# L4PER_PRM register map
Vendor: Texas Instruments
Peripheral module from a debugger description file (folder am572x).
Registers are 32-bit, access per field, reset 0x0 unless marked. A register's access mark holds for its fields unless they carry their own. Offsets are as the file gives them; lines under a group give offsets from that group; [hi:lo] are bit positions; {n}, {i} and the like mark numbered series; 'fields as' and 'values as' point back to an identical list; <NAME> marks a mode.

## L4PER_PRM (part 1 of 2)
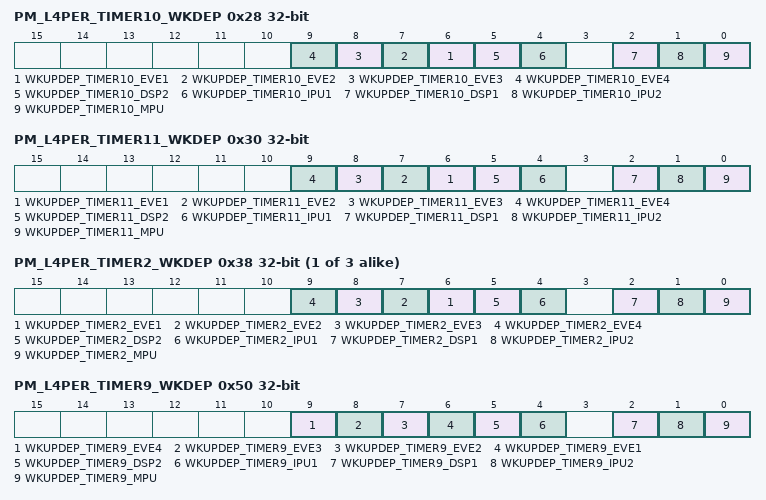
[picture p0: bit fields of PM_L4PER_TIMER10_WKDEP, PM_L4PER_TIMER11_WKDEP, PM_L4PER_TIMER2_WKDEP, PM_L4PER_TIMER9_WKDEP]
0x28 PM_L4PER_TIMER10_WKDEP — This register controls wakeup dependency based on TIMER10 service requests.
  [all] fields
    0=DISABLED (Dependency is disabled); 1=ENABLED (Dependency is enabled)
  [n+5] WKUPDEP_TIMER10_EVE{n} rw (n=1..4) — Wakeup dependency from TIMER10 module (SWakeup IRQ signal) towards EVE{n} + L3_MAIN1 + L4PER1 + L4PER2 + L4PER3 domains
  [5] WKUPDEP_TIMER10_DSP2 rw — Wakeup dependency from TIMER10 module (SWakeup IRQ signal) towards DSP2 + L3_MAIN1 + L4PER1 + L4PER2 + L4PER3 domains
  [4] WKUPDEP_TIMER10_IPU1 rw — Wakeup dependency from TIMER10 module (SWakeup IRQ signal) towards IPU1 + L3_MAIN1 + L4PER1 + L4PER2 + L4PER3 domains
  [2] WKUPDEP_TIMER10_DSP1 rw — Wakeup dependency from TIMER10 module (SWakeup IRQ signal) towards DSP + L3MAIN1 + L4PER1 + L4PER2 + L4PER3 domains
  [1] WKUPDEP_TIMER10_IPU2 rw — Wakeup dependency from TIMER10 module (SWakeup IRQ signal) towards IPU2 + L3_MAIN1 + L4PER1 + L4PER2 + L4PER3 domains
  [0] WKUPDEP_TIMER10_MPU rw — Wakeup dependency from TIMER10 module (SWakeup IRQ signal) towards MPU + L3_MAIN1 + L4PER1 + L4PER2 + L4PER3 domains
0x30 PM_L4PER_TIMER11_WKDEP — This register controls wakeup dependency based on TIMER11 service requests.
  [all] fields
    values as the fields of PM_L4PER_TIMER10_WKDEP
  [n+5] WKUPDEP_TIMER11_EVE{n} rw (n=1..4) — Wakeup dependency from TIMER11 module (SWakeup IRQ signal) towards EVE{n} + L3_MAIN1 + L4PER1 + L4PER2 + L4PER3 domains
  [5] WKUPDEP_TIMER11_DSP2 rw — Wakeup dependency from TIMER11 module (SWakeup IRQ signal) towards DSP2 + L3_MAIN1 + L4PER1 + L4PER2 + L4PER3 domains
  [4] WKUPDEP_TIMER11_IPU1 rw — Wakeup dependency from TIMER11 module (SWakeup IRQ signal) towards IPU1 + L3_MAIN1 + L4PER1 + L4PER2 + L4PER3 domains
  [2] WKUPDEP_TIMER11_DSP1 rw — Wakeup dependency from TIMER11 module (SWakeup IRQ signal) towards DSP + L3MAIN1 + L4PER1 + L4PER2 + L4PER3 domains
  [1] WKUPDEP_TIMER11_IPU2 rw — Wakeup dependency from TIMER11 module (SWakeup IRQ signal) towards IPU2 + L3_MAIN1 + L4PER1 + L4PER2 + L4PER3 domains
  [0] WKUPDEP_TIMER11_MPU rw — Wakeup dependency from TIMER11 module (SWakeup IRQ signal) towards MPU + L3_MAIN1 + L4PER1 + L4PER2 + L4PER3 domains
{0x28+8i} PM_L4PER_TIMER{i}_WKDEP (i=2..4) — This register controls wakeup dependency based on TIMER{i} service requests.
  [all] fields
    values as the fields of PM_L4PER_TIMER10_WKDEP
  [n+5] WKUPDEP_TIMER{i}_EVE{n} rw (n=1..4) — Wakeup dependency from TIMER{i} module (SWakeup IRQ signal) towards EVE{n} + L3_MAIN1 + L4PER1 + L4PER2 + L4PER3 domains
  [5] WKUPDEP_TIMER{i}_DSP2 rw — Wakeup dependency from TIMER{i} module (SWakeup IRQ signal) towards DSP2 + L3_MAIN1 + L4PER1 + L4PER2 + L4PER3 domains
  [4] WKUPDEP_TIMER{i}_IPU1 rw — Wakeup dependency from TIMER{i} module (SWakeup IRQ signal) towards IPU1 + L3_MAIN1 + L4PER1 + L4PER2 + L4PER3 domains
  [2] WKUPDEP_TIMER{i}_DSP1 rw — Wakeup dependency from TIMER{i} module (SWakeup IRQ signal) towards DSP + L3MAIN1 + L4PER1 + L4PER2 + L4PER3 domains
  [1] WKUPDEP_TIMER{i}_IPU2 rw — Wakeup dependency from TIMER{i} module (SWakeup IRQ signal) towards IPU2 + L3_MAIN1 + L4PER1 + L4PER2 + L4PER3 domains
  [0] WKUPDEP_TIMER{i}_MPU rw — Wakeup dependency from TIMER{i} module (SWakeup IRQ signal) towards MPU + L3_MAIN1 + L4PER1 + L4PER2 + L4PER3 domains
0x50 PM_L4PER_TIMER9_WKDEP — This register controls wakeup dependency based on TIMER9 service requests.
  [all] fields
    values as the fields of PM_L4PER_TIMER10_WKDEP
  [9] WKUPDEP_TIMER9_EVE4 rw — Wakeup dependency from TIMER9 module (SWakeup IRQ signal) towards EVE4 + L3_MAIN1 + L4PER1 + L4PER2 + L4PER3 domains
  [8] WKUPDEP_TIMER9_EVE3 rw — Wakeup dependency from TIMER9 module (SWakeup IRQ signal) towards EVE3 + L3_MAIN1 + L4PER1 + L4PER2 + L4PER3 domains
  [7] WKUPDEP_TIMER9_EVE2 rw — ×(SWakeup IRQ signal) towards EVE2 + L3_MAIN1 + L4PER1 + L4PER2 + L4PER3 domains
  [6] WKUPDEP_TIMER9_EVE1 rw — Wakeup dependency from TIMER9 module (SWakeup IRQ signal) towards EVE1 + L3_MAIN1 + L4PER1 + L4PER2 + L4PER3 domains
  [5] WKUPDEP_TIMER9_DSP2 rw — Wakeup dependency from TIMER9 module (SWakeup IRQ signal) towards DSP2 + L3_MAIN1 + L4PER1 + L4PER2 + L4PER3 domains
  [4] WKUPDEP_TIMER9_IPU1 rw — Wakeup dependency from TIMER9 module (SWakeup IRQ signal) towards IPU1 + L3_MAIN1 + L4PER1 + L4PER2 + L4PER3 domains
  [2] WKUPDEP_TIMER9_DSP1 rw — Wakeup dependency from TIMER9 module (SWakeup IRQ signal) towards DSP + L3MAIN1 + L4PER1 + L4PER2 + L4PER3 domains
  [1] WKUPDEP_TIMER9_IPU2 rw — Wakeup dependency from TIMER9 module (SWakeup IRQ signal) towards IPU2 + L3_MAIN1 + L4PER1 + L4PER2 + L4PER3 domains
  [0] WKUPDEP_TIMER9_MPU rw — Wakeup dependency from TIMER9 module (SWakeup IRQ signal) towards MPU + L3_MAIN1 + L4PER1 + L4PER2 + L4PER3 domains
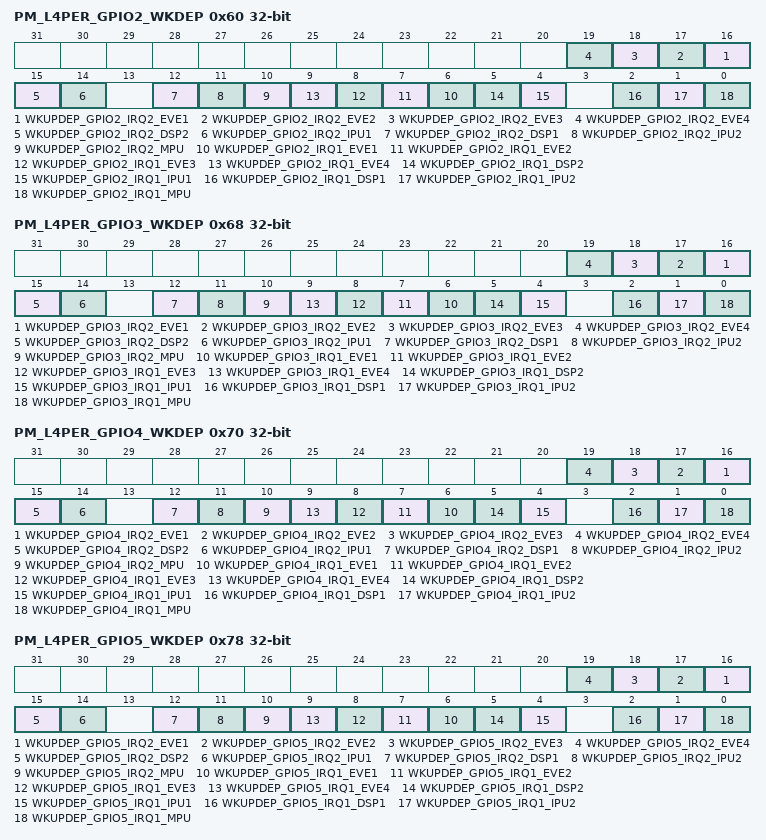
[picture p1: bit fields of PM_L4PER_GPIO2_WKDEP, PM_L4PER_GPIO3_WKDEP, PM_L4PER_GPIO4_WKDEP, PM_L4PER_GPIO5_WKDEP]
0x60 PM_L4PER_GPIO2_WKDEP — This register controls wakeup dependency based on GPIO2 service requests.
  [all] fields
    values as the fields of PM_L4PER_TIMER10_WKDEP
  [n+15] WKUPDEP_GPIO2_IRQ2_EVE{n} rw (n=1..4) — Wakeup dependency from GPIO2 module (SWakeup signal) towards EVE{n} + L3_MAIN1 + L4PER1 + L4PER2 + L4PER3 domains
  [15] WKUPDEP_GPIO2_IRQ2_DSP2 rw — Wakeup dependency from GPIO2 module (SWakeup signal) towards DSP2 + L3_MAIN1 + L4PER1 + L4PER2 + L4PER3 domains
  [14] WKUPDEP_GPIO2_IRQ2_IPU1 rw — Wakeup dependency from GPIO2 module (SWakeup signal) towards IPU1 + L3_MAIN1 + L4PER1 + L4PER2 + L4PER3 domains
  [12] WKUPDEP_GPIO2_IRQ2_DSP1 rw — Wakeup dependency from GPIO2 module (SWakeup signal) towards DSP + L3MAIN1 + L4PER1 + L4PER2 + L4PER3 domains
  [11] WKUPDEP_GPIO2_IRQ2_IPU2 rw — Wakeup dependency from GPIO2 module (SWakeup signal) towards IPU2 + L3_MAIN1 + L4PER1 + L4PER2 + L4PER3 domains
  [10] WKUPDEP_GPIO2_IRQ2_MPU rw — Wakeup dependency from GPIO2 module (SWakeup signal) towards MPU + L3_MAIN1 + L4PER1 + L4PER2 + L4PER3 domains
  [n+5] WKUPDEP_GPIO2_IRQ1_EVE{n} rw (n=1..4) — Wakeup dependency from GPIO2 module (SWakeup signal) towards EVE{n} + L3_MAIN1 + L4PER1 + L4PER2 + L4PER3 domains
  [5] WKUPDEP_GPIO2_IRQ1_DSP2 rw — Wakeup dependency from GPIO2 module (SWakeup signal) towards DSP2 + L3_MAIN1 + L4PER1 + L4PER2 + L4PER3 domains
  [4] WKUPDEP_GPIO2_IRQ1_IPU1 rw — Wakeup dependency from GPIO2 module (SWakeup signal) towards IPU1 + L3_MAIN1 + L4PER1 + L4PER2 + L4PER3 domains
  [2] WKUPDEP_GPIO2_IRQ1_DSP1 rw — Wakeup dependency from GPIO2 module (SWakeup signal) towards DSP + L3MAIN1 + L4PER1 + L4PER2 + L4PER3 domains
  [1] WKUPDEP_GPIO2_IRQ1_IPU2 rw — Wakeup dependency from GPIO2 module (SWakeup signal) towards IPU2 + L3_MAIN1 + L4PER1 + L4PER2 + L4PER3 domains
  [0] WKUPDEP_GPIO2_IRQ1_MPU rw — Wakeup dependency from GPIO2 module (SWakeup signal for POROCPSINTERRUPT1 ) towards MPU + L3_MAIN1 + L4PER1 + L4PER2 + L4PER3 domains
0x68 PM_L4PER_GPIO3_WKDEP — This register controls wakeup dependency based on GPIO3 service requests.
  [all] fields
    values as the fields of PM_L4PER_TIMER10_WKDEP
  [n+15] WKUPDEP_GPIO3_IRQ2_EVE{n} rw (n=1..4) — Wakeup dependency from GPIO3 module (SWakeup signal) towards EVE{n} + L3_MAIN1 + L4PER1 + L4PER2 + L4PER3 domains
  [15] WKUPDEP_GPIO3_IRQ2_DSP2 rw — Wakeup dependency from GPIO3 module (SWakeup signal) towards DSP2 + L3_MAIN1 + L4PER1 + L4PER2 + L4PER3 domains
  [14] WKUPDEP_GPIO3_IRQ2_IPU1 rw — Wakeup dependency from GPIO3 module (SWakeup signal) towards IPU1 + L3_MAIN1 + L4PER1 + L4PER2 + L4PER3 domains
  [12] WKUPDEP_GPIO3_IRQ2_DSP1 rw — Wakeup dependency from GPIO3 module (SWakeup signal) towards DSP + L3MAIN1 + L4PER1 + L4PER2 + L4PER3 domains
  [11] WKUPDEP_GPIO3_IRQ2_IPU2 rw — Wakeup dependency from GPIO3 module (SWakeup signal) towards IPU2 + L3_MAIN1 + L4PER1 + L4PER2 + L4PER3 domains
  [10] WKUPDEP_GPIO3_IRQ2_MPU rw — Wakeup dependency from GPIO3 module (SWakeup signal) towards MPU + L3_MAIN1 + L4PER1 + L4PER2 + L4PER3 domains
  [n+5] WKUPDEP_GPIO3_IRQ1_EVE{n} rw (n=1..4) — Wakeup dependency from GPIO3 module (SWakeup signal) towards EVE{n} + L3_MAIN1 + L4PER1 + L4PER2 + L4PER3 domains
  [5] WKUPDEP_GPIO3_IRQ1_DSP2 rw — Wakeup dependency from GPIO3 module (SWakeup signal) towards DSP2 + L3_MAIN1 + L4PER1 + L4PER2 + L4PER3 domains
  [4] WKUPDEP_GPIO3_IRQ1_IPU1 rw — Wakeup dependency from GPIO3 module (SWakeup signal) towards IPU1 + L3_MAIN1 + L4PER1 + L4PER2 + L4PER3 domains
  [2] WKUPDEP_GPIO3_IRQ1_DSP1 rw — Wakeup dependency from GPIO3 module (SWakeup signal) towards DSP + L3MAIN1 + L4PER1 + L4PER2 + L4PER3 domains
  [1] WKUPDEP_GPIO3_IRQ1_IPU2 rw — 3Wakeup dependency from GPIO3 module (SWakeup signal) towards IPU2 + L3_MAIN1 + L4PER1 + L4PER2 + L4PER3 domains
  [0] WKUPDEP_GPIO3_IRQ1_MPU rw — Wakeup dependency from GPIO3 module (SWakeup signal) towards MPU + L3_MAIN1 + L4PER1 + L4PER2 + L4PER3 domains
0x70 PM_L4PER_GPIO4_WKDEP — This register controls wakeup dependency based on GPIO4 service requests.
  [all] fields
    values as the fields of PM_L4PER_TIMER10_WKDEP
  [n+15] WKUPDEP_GPIO4_IRQ2_EVE{n} rw (n=1..4) — Wakeup dependency from GPIO4 module (SWakeup signal) towards EVE{n} + L3_MAIN1 + L4PER1 + L4PER2 + L4PER3 domains
  [15] WKUPDEP_GPIO4_IRQ2_DSP2 rw — Wakeup dependency from GPIO4 module (SWakeup signal) towards DSP2 + L3_MAIN1 + L4PER1 + L4PER2 + L4PER3 domains
  [14] WKUPDEP_GPIO4_IRQ2_IPU1 rw — Wakeup dependency from GPIO4 module (SWakeup signal) towards IPU1 + L3_MAIN1 + L4PER1 + L4PER2 + L4PER3 domains
  [12] WKUPDEP_GPIO4_IRQ2_DSP1 rw — Wakeup dependency from GPIO4 module (SWakeup signal) towards DSP + L3MAIN1 + L4PER1 + L4PER2 + L4PER3 domains
  [11] WKUPDEP_GPIO4_IRQ2_IPU2 rw — Wakeup dependency from GPIO4 module (SWakeup signal) towards IPU2 + L3_MAIN1 + L4PER1 + L4PER2 + L4PER3 domains
  [10] WKUPDEP_GPIO4_IRQ2_MPU rw — Wakeup dependency from GPIO4 module (SWakeup signal) towards MPU + L3_MAIN1 + L4PER1 + L4PER2 + L4PER3 domains
  [n+5] WKUPDEP_GPIO4_IRQ1_EVE{n} rw (n=1..4) — Wakeup dependency from GPIO4 module (SWakeup signal) towards EVE{n} + L3_MAIN1 + L4PER1 + L4PER2 + L4PER3 domains
  [5] WKUPDEP_GPIO4_IRQ1_DSP2 rw — Wakeup dependency from GPIO4 module (SWakeup signal) towards DSP2 + L3_MAIN1 + L4PER1 + L4PER2 + L4PER3 domains
  [4] WKUPDEP_GPIO4_IRQ1_IPU1 rw — Wakeup dependency from GPIO4 module (SWakeup signal) towards IPU1 + L3_MAIN1 + L4PER1 + L4PER2 + L4PER3 domains
  [2] WKUPDEP_GPIO4_IRQ1_DSP1 rw — Wakeup dependency from GPIO4 module (SWakeup signal) towards DSP + L3MAIN1 + L4PER1 + L4PER2 + L4PER3 domains
  [1] WKUPDEP_GPIO4_IRQ1_IPU2 rw — Wakeup dependency from GPIO4 module (SWakeup signal) towards IPU2 + L3_MAIN1 + L4PER1 + L4PER2 + L4PER3 domains
  [0] WKUPDEP_GPIO4_IRQ1_MPU rw — Wakeup dependency from GPIO4 module (SWakeup signal) towards MPU + L3_MAIN1 + L4PER1 + L4PER2 + L4PER3 domains
0x78 PM_L4PER_GPIO5_WKDEP — This register controls wakeup dependency based on GPIO5 service requests.
  [all] fields
    values as the fields of PM_L4PER_TIMER10_WKDEP
  [n+15] WKUPDEP_GPIO5_IRQ2_EVE{n} rw (n=1..4) — Wakeup dependency from GPIO5 module (SWakeup signal) towards EVE{n} + L3_MAIN1 + L4PER1 + L4PER2 + L4PER3 domains
  [15] WKUPDEP_GPIO5_IRQ2_DSP2 rw — Wakeup dependency from GPIO5 module (SWakeup signal) towards DSP2 + L3_MAIN1 + L4PER1 + L4PER2 + L4PER3 domains
  [14] WKUPDEP_GPIO5_IRQ2_IPU1 rw — Wakeup dependency from GPIO5 module (SWakeup signal) towards IPU1 + L3_MAIN1 + L4PER1 + L4PER2 + L4PER3 domains
  [12] WKUPDEP_GPIO5_IRQ2_DSP1 rw — Wakeup dependency from GPIO5 module (SWakeup signal) towards DSP + L3MAIN1 + L4PER1 + L4PER2 + L4PER3 domains
  [11] WKUPDEP_GPIO5_IRQ2_IPU2 rw — Wakeup dependency from GPIO5 module (SWakeup signal) towards IPU2 + L3_MAIN1 + L4PER1 + L4PER2 + L4PER3 domains
  [10] WKUPDEP_GPIO5_IRQ2_MPU rw — Wakeup dependency from GPIO5 module (SWakeup signal) towards MPU + L3_MAIN1 + L4PER1 + L4PER2 + L4PER3 domains
  [n+5] WKUPDEP_GPIO5_IRQ1_EVE{n} rw (n=1..4) — Wakeup dependency from GPIO5 module (SWakeup signal) towards EVE{n} + L3_MAIN1 + L4PER1 + L4PER2 + L4PER3 domains
  [5] WKUPDEP_GPIO5_IRQ1_DSP2 rw — Wakeup dependency from GPIO5 module (SWakeup signal) towards DSP2 + L3_MAIN1 + L4PER1 + L4PER2 + L4PER3 domains
  [4] WKUPDEP_GPIO5_IRQ1_IPU1 rw — Wakeup dependency from GPIO5 module (SWakeup signal) towards IPU1 + L3_MAIN1 + L4PER1 + L4PER2 + L4PER3 domains
  [2] WKUPDEP_GPIO5_IRQ1_DSP1 rw — Wakeup dependency from GPIO5 module (SWakeup signal) towards DSP + L3MAIN1 + L4PER1 + L4PER2 + L4PER3 domains
  [1] WKUPDEP_GPIO5_IRQ1_IPU2 rw — 5Wakeup dependency from GPIO5 module (SWakeup signal) towards IPU2 + L3_MAIN1 + L4PER1 + L4PER2 + L4PER3 domains
  [0] WKUPDEP_GPIO5_IRQ1_MPU rw — Wakeup dependency from GPIO5 module (SWakeup signal) towards MPU + L3_MAIN1 + L4PER1 + L4PER2 + L4PER3 domains
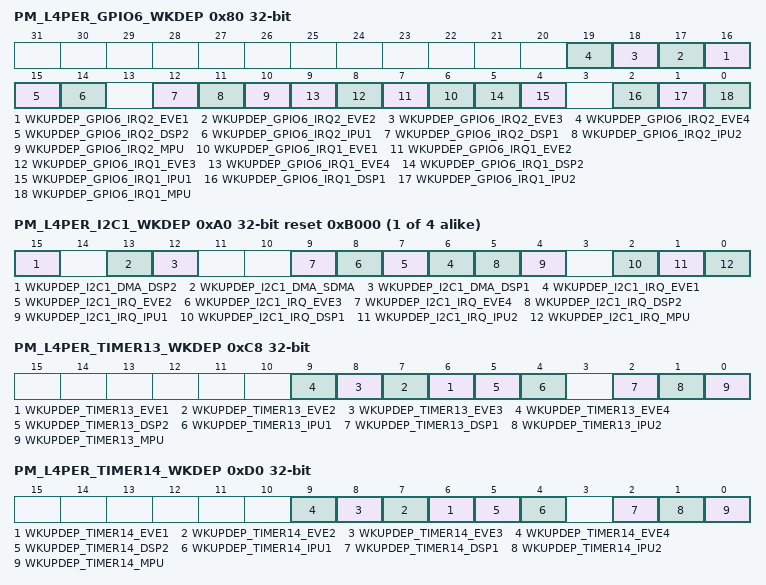
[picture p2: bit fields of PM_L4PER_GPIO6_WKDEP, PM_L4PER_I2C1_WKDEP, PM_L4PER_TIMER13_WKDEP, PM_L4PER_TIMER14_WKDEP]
0x80 PM_L4PER_GPIO6_WKDEP — This register controls wakeup dependency based on GPIO6 service requests.
  [all] fields
    values as the fields of PM_L4PER_TIMER10_WKDEP
  [n+15] WKUPDEP_GPIO6_IRQ2_EVE{n} rw (n=1..4) — Wakeup dependency from GPIO6 module (SWakeup signal) towards EVE{n} + L3_MAIN1 + L4PER1 + L4PER2 + L4PER3 domains
  [15] WKUPDEP_GPIO6_IRQ2_DSP2 rw — Wakeup dependency from GPIO6 module (SWakeup signal) towards DSP2 + L3_MAIN1 + L4PER1 + L4PER2 + L4PER3 domains
  [14] WKUPDEP_GPIO6_IRQ2_IPU1 rw — Wakeup dependency from GPIO6 module (SWakeup signal) towards IPU1 + L3_MAIN1 + L4PER1 + L4PER2 + L4PER3 domains
  [12] WKUPDEP_GPIO6_IRQ2_DSP1 rw — Wakeup dependency from GPIO6 module (SWakeup signal) towards DSP + L3MAIN1 + L4PER1 + L4PER2 + L4PER3 domains
  [11] WKUPDEP_GPIO6_IRQ2_IPU2 rw — Wakeup dependency from GPIO6 module (SWakeup signal) towards IPU2 + L3_MAIN1 + L4PER1 + L4PER2 + L4PER3 domains
  [10] WKUPDEP_GPIO6_IRQ2_MPU rw — Wakeup dependency from GPIO6 module (SWakeup signal) towards MPU + L3_MAIN1 + L4PER1 + L4PER2 + L4PER3 domains
  [n+5] WKUPDEP_GPIO6_IRQ1_EVE{n} rw (n=1..4) — Wakeup dependency from GPIO6 module (SWakeup signal) towards EVE{n} + L3_MAIN1 + L4PER1 + L4PER2 + L4PER3 domains
  [5] WKUPDEP_GPIO6_IRQ1_DSP2 rw — Wakeup dependency from GPIO6 module (SWakeup signal) towards DSP2 + L3_MAIN1 + L4PER1 + L4PER2 + L4PER3 domains
  [4] WKUPDEP_GPIO6_IRQ1_IPU1 rw — Wakeup dependency from GPIO6 module (SWakeup signal) towards IPU1 + L3_MAIN1 + L4PER1 + L4PER2 + L4PER3 domains
  [2] WKUPDEP_GPIO6_IRQ1_DSP1 rw — Wakeup dependency from GPIO6 module (SWakeup signal) towards DSP + L3MAIN1 + L4PER1 + L4PER2 + L4PER3 domains
  [1] WKUPDEP_GPIO6_IRQ1_IPU2 rw — 5Wakeup dependency from GPIO6 module (SWakeup signal) towards IPU2 + L3_MAIN1 + L4PER1 + L4PER2 + L4PER3 domains
  [0] WKUPDEP_GPIO6_IRQ1_MPU rw — Wakeup dependency from GPIO6 module (SWakeup signal) towards MPU + L3_MAIN1 + L4PER1 + L4PER2 + L4PER3 domains
{0x98+8i} PM_L4PER_I2C{i}_WKDEP reset 0xB000 (i=1..4) — This register controls wakeup dependency based on I2C{i} service requests.
  [all] fields
    values as the fields of PM_L4PER_TIMER10_WKDEP
  [15] WKUPDEP_I2C{i}_DMA_DSP2 rw — Wakeup dependency from I2C{i} module (SWakeup_dma signal) towards DSP2 + L3_MAIN1 + L4PER1 + L4PER2 + L4PER3 domains
  [13] WKUPDEP_I2C{i}_DMA_SDMA rw — Wakeup dependency from I2C{i} module (SWakeup_dma signal) towards SDMA + L3MAIN1 + L4PER1 + L4PER2 + L4PER3 domains
  [12] WKUPDEP_I2C{i}_DMA_DSP1 rw — Wakeup dependency from I2C{i} module (SWakeup_dma signal) towards DSP + L3MAIN1 + L4PER1 + L4PER2 + L4PER3 domains
  [n+5] WKUPDEP_I2C{i}_IRQ_EVE{n} rw (n=1..4) — Wakeup dependency from I2C{i} module (SWakeup IRQ signal) towards EVE{n} + L3_MAIN1 + L4PER1 + L4PER2 + L4PER3 domains
  [5] WKUPDEP_I2C{i}_IRQ_DSP2 rw — Wakeup dependency from I2C{i} module (SWakeup IRQ signal) towards DSP2 + L3_MAIN1 + L4PER1 + L4PER2 + L4PER3 domains
  [4] WKUPDEP_I2C{i}_IRQ_IPU1 rw — Wakeup dependency from I2C{i} module (SWakeup IRQ signal) towards IPU1 + L3_MAIN1 + L4PER1 + L4PER2 + L4PER3 domains
  [2] WKUPDEP_I2C{i}_IRQ_DSP1 rw — Wakeup dependency from I2C{i} module (SWakeup IRQ signal) towards DSP + L3MAIN1 + L4PER1 + L4PER2 + L4PER3 domains
  [1] WKUPDEP_I2C{i}_IRQ_IPU2 rw — Wakeup dependency from I2C{i} module (SWakeup IRQ signal) towards IPU2 + L3_MAIN1 + L4PER1 + L4PER2 + L4PER3 domains
  [0] WKUPDEP_I2C{i}_IRQ_MPU rw — Wakeup dependency from I2C{i} module (SWakeup IRQ signal) towards MPU + L3_MAIN1 + L4PER1 + L4PER2 + L4PER3 domains
0xC8 PM_L4PER_TIMER13_WKDEP — This register controls wakeup dependency based on TIMER13 service requests.
  [all] fields
    values as the fields of PM_L4PER_TIMER10_WKDEP
  [n+5] WKUPDEP_TIMER13_EVE{n} rw (n=1..4) — Wakeup dependency from TIMER13 module (SWakeup IRQ signal) towards EVE{n} + L3_MAIN1 + L4PER1 + L4PER2 + L4PER3 domains
  [5] WKUPDEP_TIMER13_DSP2 rw — Wakeup dependency from TIMER13 module (SWakeup IRQ signal) towards DSP2 + L3_MAIN1 + L4PER1 + L4PER2 + L4PER3 domains
  [4] WKUPDEP_TIMER13_IPU1 rw — Wakeup dependency from TIMER13 module (SWakeup IRQ signal) towards IPU1 + L3_MAIN1 + L4PER1 + L4PER2 + L4PER3 domains
  [2] WKUPDEP_TIMER13_DSP1 rw — Wakeup dependency from TIMER13 module (SWakeup IRQ signal) towards DSP + L3MAIN1 + L4PER1 + L4PER2 + L4PER3 domains
  [1] WKUPDEP_TIMER13_IPU2 rw — Wakeup dependency from TIMER13 module (SWakeup IRQ signal) towards IPU2 + L3_MAIN1 + L4PER1 + L4PER2 + L4PER3 domains
  [0] WKUPDEP_TIMER13_MPU rw — Wakeup dependency from TIMER13 module (SWakeup IRQ signal) towards MPU + L3_MAIN1 + L4PER1 + L4PER2 + L4PER3 domains
0xD0 PM_L4PER_TIMER14_WKDEP — This register controls wakeup dependency based on TIMER14 service requests.
  [all] fields
    values as the fields of PM_L4PER_TIMER10_WKDEP
  [n+5] WKUPDEP_TIMER14_EVE{n} rw (n=1..4) — Wakeup dependency from TIMER14 module (SWakeup IRQ signal) towards EVE{n} + L3_MAIN1 + L4PER1 + L4PER2 + L4PER3 domains
  [5] WKUPDEP_TIMER14_DSP2 rw — Wakeup dependency from TIMER14 module (SWakeup IRQ signal) towards DSP2 + L3_MAIN1 + L4PER1 + L4PER2 + L4PER3 domains
  [4] WKUPDEP_TIMER14_IPU1 rw — Wakeup dependency from TIMER14 module (SWakeup IRQ signal) towards IPU1 + L3_MAIN1 + L4PER1 + L4PER2 + L4PER3 domains
  [2] WKUPDEP_TIMER14_DSP1 rw — Wakeup dependency from TIMER14 module (SWakeup IRQ signal) towards DSP + L3MAIN1 + L4PER1 + L4PER2 + L4PER3 domains
  [1] WKUPDEP_TIMER14_IPU2 rw — Wakeup dependency from TIMER14 module (SWakeup IRQ signal) towards IPU2 + L3_MAIN1 + L4PER1 + L4PER2 + L4PER3 domains
  [0] WKUPDEP_TIMER14_MPU rw — Wakeup dependency from TIMER14 module (SWakeup IRQ signal) towards MPU + L3_MAIN1 + L4PER1 + L4PER2 + L4PER3 domains
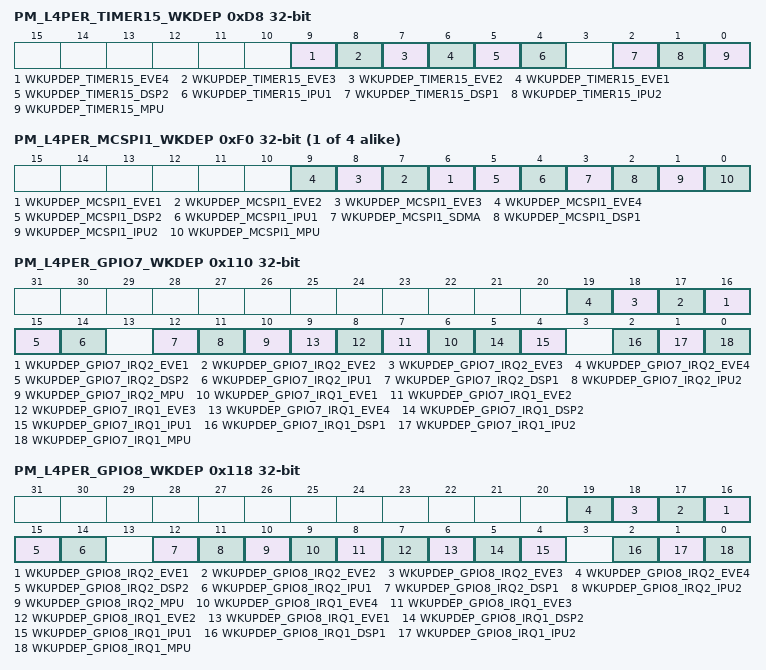
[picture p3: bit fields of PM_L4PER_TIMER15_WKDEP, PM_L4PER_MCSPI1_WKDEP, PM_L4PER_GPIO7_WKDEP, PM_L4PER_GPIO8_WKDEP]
0xD8 PM_L4PER_TIMER15_WKDEP — This register controls wakeup dependency based on TIMER15 service requests.
  [all] fields
    values as the fields of PM_L4PER_TIMER10_WKDEP
  [9] WKUPDEP_TIMER15_EVE4 rw — 5Wakeup dependency from TIMER15 module (SWakeup IRQ signal) towards EVE4 + L3_MAIN1 + L4PER1 + L4PER2 + L4PER3 domains
  [8] WKUPDEP_TIMER15_EVE3 rw — Wakeup dependency from TIMER15 module (SWakeup IRQ signal) towards EVE3 + L3_MAIN1 + L4PER1 + L4PER2 + L4PER3 domains
  [7] WKUPDEP_TIMER15_EVE2 rw — Wakeup dependency from TIMER15 module (SWakeup IRQ signal) towards EVE2 + L3_MAIN1 + L4PER1 + L4PER2 + L4PER3 domains
  [6] WKUPDEP_TIMER15_EVE1 rw — Wakeup dependency from TIMER15 module (SWakeup IRQ signal) towards EVE1 + L3_MAIN1 + L4PER1 + L4PER2 + L4PER3 domains
  [5] WKUPDEP_TIMER15_DSP2 rw — Wakeup dependency from TIMER15 module (SWakeup IRQ signal) towards DSP2 + L3_MAIN1 + L4PER1 + L4PER2 + L4PER3 domains
  [4] WKUPDEP_TIMER15_IPU1 rw — Wakeup dependency from TIMER15 module (SWakeup IRQ signal) towards IPU1 + L3_MAIN1 + L4PER1 + L4PER2 + L4PER3 domains
  [2] WKUPDEP_TIMER15_DSP1 rw — Wakeup dependency from TIMER15 module (SWakeup IRQ signal) towards DSP + L3MAIN1 + L4PER1 + L4PER2 + L4PER3 domains
  [1] WKUPDEP_TIMER15_IPU2 rw — Wakeup dependency from TIMER15 module (SWakeup IRQ signal) towards IPU2 + L3_MAIN1 + L4PER1 + L4PER2 + L4PER3 domains
  [0] WKUPDEP_TIMER15_MPU rw — Wakeup dependency from TIMER15 module (SWakeup IRQ signal) towards MPU + L3_MAIN1 + L4PER1 + L4PER2 + L4PER3 domains
{0xE8+8i} PM_L4PER_MCSPI{i}_WKDEP (i=1..4) — This register controls wakeup dependency based on MCSPI{i} service requests.
  [all] fields
    values as the fields of PM_L4PER_TIMER10_WKDEP
  [n+5] WKUPDEP_MCSPI{i}_EVE{n} rw (n=1..4) — Wakeup dependency from MCSPI{i} module (SWakeup signal) towards EVE{n} + L3_MAIN1 + L4PER1 + L4PER2 + L4PER3 domains
  [5] WKUPDEP_MCSPI{i}_DSP2 rw — Wakeup dependency from MCSPI{i} module (SWakeup signal) towards DSP2 + L3_MAIN1 + L4PER1 + L4PER2 + L4PER3 domains
  [4] WKUPDEP_MCSPI{i}_IPU1 rw — Wakeup dependency from MCSPI{i} module (SWakeup signal) towards IPU1 + L3_MAIN1 + L4PER1 + L4PER2 + L4PER3 domains
  [3] WKUPDEP_MCSPI{i}_SDMA rw — Wakeup dependency from MCSPI{i} module (SWakeup signal) towards SDMA + L3MAIN1 + L4PER1 + L4PER2 + L4PER3 domains
  [2] WKUPDEP_MCSPI{i}_DSP1 rw — Wakeup dependency from MCSPI{i} module (SWakeup signal) towards DSP + L3MAIN1 + L4PER1 + L4PER2 + L4PER3 domains
  [1] WKUPDEP_MCSPI{i}_IPU2 rw — Wakeup dependency from MCSPI{i} module (SWakeup signal) towards IPU2 + L3_MAIN1 + L4PER1 + L4PER2 + L4PER3 domains
  [0] WKUPDEP_MCSPI{i}_MPU rw — Wakeup dependency from MCSPI{i} module (SWakeup signal) towards MPU + L3_MAIN1 + L4PER1 + L4PER2 + L4PER3 domains
0x110 PM_L4PER_GPIO7_WKDEP — This register controls wakeup dependency based on GPIO7 service requests.
  [all] fields
    values as the fields of PM_L4PER_TIMER10_WKDEP
  [n+15] WKUPDEP_GPIO7_IRQ2_EVE{n} rw (n=1..4) — Wakeup dependency from GPIO7 module (SWakeup signal) towards EVE{n} + L3_MAIN1 + L4PER1 + L4PER2 + L4PER3 domains
  [15] WKUPDEP_GPIO7_IRQ2_DSP2 rw — Wakeup dependency from GPIO7 module (SWakeup signal) towards DSP2 + L3_MAIN1 + L4PER1 + L4PER2 + L4PER3 domains
  [14] WKUPDEP_GPIO7_IRQ2_IPU1 rw — Wakeup dependency from GPIO7 module (SWakeup signal) towards IPU1 + L3_MAIN1 + L4PER1 + L4PER2 + L4PER3 domains
  [12] WKUPDEP_GPIO7_IRQ2_DSP1 rw — Wakeup dependency from GPIO7 module (SWakeup signal) towards DSP + L3MAIN1 + L4PER1 + L4PER2 + L4PER3 domains
  [11] WKUPDEP_GPIO7_IRQ2_IPU2 rw — Wakeup dependency from GPIO7 module (SWakeup signal) towards IPU2 + L3_MAIN1 + L4PER1 + L4PER2 + L4PER3 domains
  [10] WKUPDEP_GPIO7_IRQ2_MPU rw — Wakeup dependency from GPIO7 module (SWakeup signal) towards MPU + L3_MAIN1 + L4PER1 + L4PER2 + L4PER3 domains
  [n+5] WKUPDEP_GPIO7_IRQ1_EVE{n} rw (n=1..4) — Wakeup dependency from GPIO7 module (SWakeup signal) towards EVE{n} + L3_MAIN1 + L4PER1 + L4PER2 + L4PER3 domains
  [5] WKUPDEP_GPIO7_IRQ1_DSP2 rw — Wakeup dependency from GPIO7 module (SWakeup signal) towards DSP2 + L3_MAIN1 + L4PER1 + L4PER2 + L4PER3 domains
  [4] WKUPDEP_GPIO7_IRQ1_IPU1 rw — Wakeup dependency from GPIO7 module (SWakeup signal) towards IPU1 + L3_MAIN1 + L4PER1 + L4PER2 + L4PER3 domains
  [2] WKUPDEP_GPIO7_IRQ1_DSP1 rw — Wakeup dependency from GPIO7 module (SWakeup signal) towards DSP + L3MAIN1 + L4PER1 + L4PER2 + L4PER3 domains
  [1] WKUPDEP_GPIO7_IRQ1_IPU2 rw — 5Wakeup dependency from GPIO7 module (SWakeup signal) towards IPU2 + L3_MAIN1 + L4PER1 + L4PER2 + L4PER3 domains
  [0] WKUPDEP_GPIO7_IRQ1_MPU rw — Wakeup dependency from GPIO7 module (SWakeup signal) towards MPU + L3_MAIN1 + L4PER1 + L4PER2 + L4PER3 domains
0x118 PM_L4PER_GPIO8_WKDEP — This register controls wakeup dependency based on GPIO8 service requests.
  [all] fields
    values as the fields of PM_L4PER_TIMER10_WKDEP
  [n+15] WKUPDEP_GPIO8_IRQ2_EVE{n} rw (n=1..4) — Wakeup dependency from GPIO8 module (SWakeup signal) towards EVE{n} + L3_MAIN1 + L4PER1 + L4PER2 + L4PER3 domains
  [15] WKUPDEP_GPIO8_IRQ2_DSP2 rw — Wakeup dependency from GPIO8 module (SWakeup signal) towards DSP2 + L3_MAIN1 + L4PER1 + L4PER2 + L4PER3 domains
  [14] WKUPDEP_GPIO8_IRQ2_IPU1 rw — Wakeup dependency from GPIO8 module (SWakeup signal) towards IPU1 + L3_MAIN1 + L4PER1 + L4PER2 + L4PER3 domains
  [12] WKUPDEP_GPIO8_IRQ2_DSP1 rw — Wakeup dependency from GPIO8 module (SWakeup signal) towards DSP + L3MAIN1 + L4PER1 + L4PER2 + L4PER3 domains
  [11] WKUPDEP_GPIO8_IRQ2_IPU2 rw — Wakeup dependency from GPIO8 module (SWakeup signal) towards IPU2 + L3_MAIN1 + L4PER1 + L4PER2 + L4PER3 domains
  [10] WKUPDEP_GPIO8_IRQ2_MPU rw — Wakeup dependency from GPIO8 module (SWakeup signal) towards MPU + L3_MAIN1 + L4PER1 + L4PER2 + L4PER3 domains
  [9] WKUPDEP_GPIO8_IRQ1_EVE4 rw — Wakeup dependency from GPIO8 module (SWakeup signal) towards EVE4 + L3_MAIN1 + L4PER1 + L4PER2 + L4PER3 domains
  [8] WKUPDEP_GPIO8_IRQ1_EVE3 rw — Wakeup dependency from GPIO8 (SWakeup signal) towards EVE3 + L3_MAIN1 + L4PER1 + L4PER2 + L4PER3 domains
  [7] WKUPDEP_GPIO8_IRQ1_EVE2 rw — Wakeup dependency from GPIO8 module (SWakeup signal) towards EVE2 + L3_MAIN1 + L4PER1 + L4PER2 + L4PER3 domains
  [6] WKUPDEP_GPIO8_IRQ1_EVE1 rw — Wakeup dependency from GPIO8 module (SWakeup signal) towards EVE1 + L3_MAIN1 + L4PER1 + L4PER2 + L4PER3 domains
  [5] WKUPDEP_GPIO8_IRQ1_DSP2 rw — Wakeup dependency from GPIO8 module (SWakeup signal) towards DSP2 + L3_MAIN1 + L4PER1 + L4PER2 + L4PER3 domains
  [4] WKUPDEP_GPIO8_IRQ1_IPU1 rw — Wakeup dependency from GPIO8 module (SWakeup signal) towards IPU1 + L3_MAIN1 + L4PER1 + L4PER2 + L4PER3 domains
  [2] WKUPDEP_GPIO8_IRQ1_DSP1 rw — Wakeup dependency from GPIO8 module (SWakeup signal) towards DSP + L3MAIN1 + L4PER1 + L4PER2 + L4PER3 domains
  [1] WKUPDEP_GPIO8_IRQ1_IPU2 rw — 5Wakeup dependency from GPIO8 module (SWakeup signal) towards IPU2 + L3_MAIN1 + L4PER1 + L4PER2 + L4PER3 domains
  [0] WKUPDEP_GPIO8_IRQ1_MPU rw — Wakeup dependency from GPIO8 module (SWakeup signal) towards MPU + L3_MAIN1 + L4PER1 + L4PER2 + L4PER3 domains
